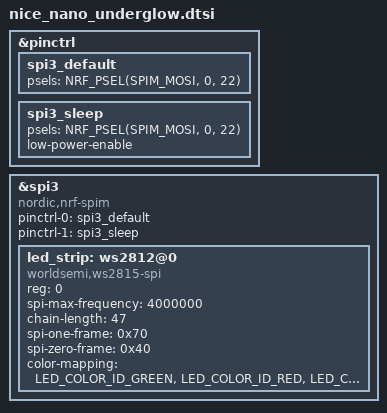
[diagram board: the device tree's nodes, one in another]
#include <dt-bindings/led/led.h>

&pinctrl {
  spi3_default: spi3_default {
    psels = <NRF_PSEL(SPIM_MOSI, 0, 22)>;
  };

  spi3_sleep: spi3_sleep {
    psels = <NRF_PSEL(SPIM_MOSI, 0, 22)>;
    low-power-enable;
  };
};

&spi3 {
  compatible = "nordic,nrf-spim";
  status = "okay";

  pinctrl-0 = <&spi3_default>;
  pinctrl-1 = <&spi3_sleep>;

  led_strip: ws2812@0 {
    compatible = "worldsemi,ws2815-spi";

    reg = <0>;
    spi-max-frequency = <4000000>;

    chain-length = <47>;
    spi-one-frame = <0x70>;
    spi-zero-frame = <0x40>;
    color-mapping = <LED_COLOR_ID_GREEN, LED_COLOR_ID_RED, LED_COLOR_ID_BLUE>;
  };
};
